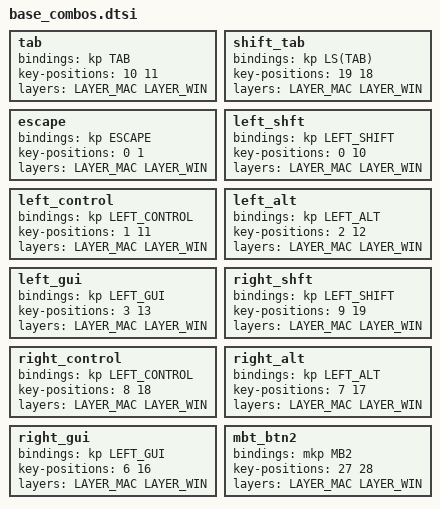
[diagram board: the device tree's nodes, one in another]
/*
 * Common typing-layer combos. Do not intercept function, number, setting,
 * auto-mouse or scroll-layer keys.
 */

        tab {
            bindings = <&kp TAB>;
            key-positions = <10 11>;
            layers = <LAYER_MAC LAYER_WIN>;
        };

        shift_tab {
            bindings = <&kp LS(TAB)>;
            key-positions = <19 18>;
            layers = <LAYER_MAC LAYER_WIN>;
        };

        escape {
            bindings = <&kp ESCAPE>;
            key-positions = <0 1>;
            layers = <LAYER_MAC LAYER_WIN>;
        };

        left_shft {
            bindings = <&kp LEFT_SHIFT>;
            key-positions = <0 10>;
            layers = <LAYER_MAC LAYER_WIN>;
        };

        left_control {
            bindings = <&kp LEFT_CONTROL>;
            key-positions = <1 11>;
            layers = <LAYER_MAC LAYER_WIN>;
        };

        left_alt {
            bindings = <&kp LEFT_ALT>;
            key-positions = <2 12>;
            layers = <LAYER_MAC LAYER_WIN>;
        };

        left_gui {
            bindings = <&kp LEFT_GUI>;
            key-positions = <3 13>;
            layers = <LAYER_MAC LAYER_WIN>;
        };

        right_shft {
            bindings = <&kp LEFT_SHIFT>;
            key-positions = <9 19>;
            layers = <LAYER_MAC LAYER_WIN>;
        };

        right_control {
            bindings = <&kp LEFT_CONTROL>;
            key-positions = <8 18>;
            layers = <LAYER_MAC LAYER_WIN>;
        };

        right_alt {
            bindings = <&kp LEFT_ALT>;
            key-positions = <7 17>;
            layers = <LAYER_MAC LAYER_WIN>;
        };

        right_gui {
            bindings = <&kp LEFT_GUI>;
            key-positions = <6 16>;
            layers = <LAYER_MAC LAYER_WIN>;
        };

        mbt_btn2 {
            bindings = <&mkp MB2>;
            key-positions = <27 28>;
            layers = <LAYER_MAC LAYER_WIN>;
        };
